# COMPUTE_CLUSTER_J7AHP0_CFG_WRAP_0_VBUSP4_CFG_AW6_CFG_MSMC1_ECC1 register map
Vendor: Texas Instruments
Peripheral module from a debugger description file (folder J7_AHP).
Registers are 32-bit, access not given, reset 0x0 unless marked. A register's access mark holds for its fields unless they carry their own. Offsets are as the file gives them; lines under a group give offsets from that group; [hi:lo] are bit positions; {n}, {i} and the like mark numbered series; 'fields as' and 'values as' point back to an identical list; <NAME> marks a mode.

## COMPUTE_CLUSTER_J7AHP0_CFG_WRAP_0_VBUSP4_CFG_AW6_CFG_MSMC1_ECC1
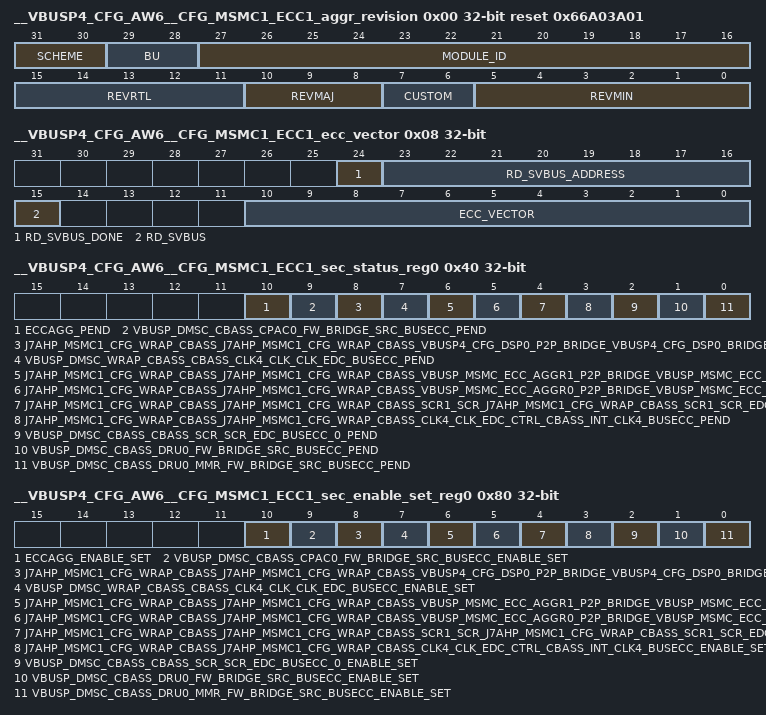
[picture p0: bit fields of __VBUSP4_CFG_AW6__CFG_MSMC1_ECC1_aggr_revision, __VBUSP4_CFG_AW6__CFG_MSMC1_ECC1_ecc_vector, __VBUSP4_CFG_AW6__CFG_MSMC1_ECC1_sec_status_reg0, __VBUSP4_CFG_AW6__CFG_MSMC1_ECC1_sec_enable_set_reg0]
0x00 __VBUSP4_CFG_AW6__CFG_MSMC1_ECC1_aggr_revision ro reset 0x66A03A01
  [31:30] SCHEME
  [29:28] BU
  [27:16] MODULE_ID
  [15:11] REVRTL — RTL version
  [10:8] REVMAJ — Major version
  [7:6] CUSTOM — Custom version
  [5:0] REVMIN — Minor version
0x08 __VBUSP4_CFG_AW6__CFG_MSMC1_ECC1_ecc_vector
  [24] RD_SVBUS_DONE — Status to indicate if read on serial VBUS is complete, write of any value will clear this bit. (access R/W1TC)
  [23:16] RD_SVBUS_ADDRESS rw — Read address
  [15] RD_SVBUS — Write 1 to trigger a read on the serial VBUS (access R/W1TS)
  [10:0] ECC_VECTOR rw — Value written to select the corresponding ECC RAM for control or status
0x0C __VBUSP4_CFG_AW6__CFG_MSMC1_ECC1_misc_status ro reset 0xB
  [10:0] NUM_RAMS — Indicates the number of RAMS serviced by the ECC aggregator
0x10 __VBUSP4_CFG_AW6__CFG_MSMC1_ECC1_reserved_svbus rw
  [31:0] DATA — Serial VBUS register data
0x3C __VBUSP4_CFG_AW6__CFG_MSMC1_ECC1_sec_eoi_reg
  [0] EOI_WR — EOI Register (access R/W1TS)
0x40 __VBUSP4_CFG_AW6__CFG_MSMC1_ECC1_sec_status_reg0
  [10] ECCAGG_PEND — Interrupt Pending Status for eccagg_pend (access R/W1TS)
  [9] VBUSP_DMSC_CBASS_CPAC0_FW_BRIDGE_SRC_BUSECC_PEND — Interrupt Pending Status for vbusp_dmsc_cbass_cpac0_fw_bridge_src_busecc_pend (access R/W1TS)
  [8] J7AHP_MSMC1_CFG_WRAP_CBASS_J7AHP_MSMC1_CFG_WRAP_CBASS_VBUSP4_CFG_DSP0_P2P_BRIDGE_VBUSP4_CFG_DSP0_BRIDGE_SRC_BUSECC_PEND — Interrupt Pending Status for j7ahp_msmc1_cfg_wrap_cbass_j7ahp_msmc1_cfg_wrap_cbass_vbusp4_cfg_dsp0_p2p_bridge_vbusp4_cfg_dsp0_bridge_src_busecc_pend (access R/W1TS)
  [7] VBUSP_DMSC_WRAP_CBASS_CBASS_CLK4_CLK_CLK_EDC_BUSECC_PEND — Interrupt Pending Status for vbusp_dmsc_wrap_cbass_cbass_clk4_clk_clk_edc_busecc_pend (access R/W1TS)
  [6] J7AHP_MSMC1_CFG_WRAP_CBASS_J7AHP_MSMC1_CFG_WRAP_CBASS_VBUSP_MSMC_ECC_AGGR1_P2P_BRIDGE_VBUSP_MSMC_ECC_AGGR1_BRIDGE_BUSECC_PEND — Interrupt Pending Status for j7ahp_msmc1_cfg_wrap_cbass_j7ahp_msmc1_cfg_wrap_cbass_vbusp_msmc_ecc_aggr1_p2p_bridge_vbusp_msmc_ecc_aggr1_bridge_busecc_pend (access R/W1TS)
  [5] J7AHP_MSMC1_CFG_WRAP_CBASS_J7AHP_MSMC1_CFG_WRAP_CBASS_VBUSP_MSMC_ECC_AGGR0_P2P_BRIDGE_VBUSP_MSMC_ECC_AGGR0_BRIDGE_SRC_BUSECC_PEND — Interrupt Pending Status for j7ahp_msmc1_cfg_wrap_cbass_j7ahp_msmc1_cfg_wrap_cbass_vbusp_msmc_ecc_aggr0_p2p_bridge_vbusp_msmc_ecc_aggr0_bridge_src_busecc_pend (access R/W1TS)
  [4] J7AHP_MSMC1_CFG_WRAP_CBASS_J7AHP_MSMC1_CFG_WRAP_CBASS_SCR1_SCR_J7AHP_MSMC1_CFG_WRAP_CBASS_SCR1_SCR_EDC_CTRL_BUSECC_PEND — Interrupt Pending Status for j7ahp_msmc1_cfg_wrap_cbass_j7ahp_msmc1_cfg_wrap_cbass_scr1_scr_j7ahp_msmc1_cfg_wrap_cbass_scr1_scr_edc_ctrl_busecc_pend (access R/W1TS)
  [3] J7AHP_MSMC1_CFG_WRAP_CBASS_J7AHP_MSMC1_CFG_WRAP_CBASS_CLK4_CLK_EDC_CTRL_CBASS_INT_CLK4_BUSECC_PEND — Interrupt Pending Status for j7ahp_msmc1_cfg_wrap_cbass_j7ahp_msmc1_cfg_wrap_cbass_clk4_clk_edc_ctrl_cbass_int_clk4_busecc_pend (access R/W1TS)
  [2] VBUSP_DMSC_CBASS_CBASS_SCR_SCR_EDC_BUSECC_0_PEND — Interrupt Pending Status for vbusp_dmsc_cbass_cbass_scr_scr_edc_busecc_0_pend (access R/W1TS)
  [1] VBUSP_DMSC_CBASS_DRU0_FW_BRIDGE_SRC_BUSECC_PEND — Interrupt Pending Status for vbusp_dmsc_cbass_dru0_fw_bridge_src_busecc_pend (access R/W1TS)
  [0] VBUSP_DMSC_CBASS_DRU0_MMR_FW_BRIDGE_SRC_BUSECC_PEND — Interrupt Pending Status for vbusp_dmsc_cbass_dru0_mmr_fw_bridge_src_busecc_pend (access R/W1TS)
0x80 __VBUSP4_CFG_AW6__CFG_MSMC1_ECC1_sec_enable_set_reg0
  [10] ECCAGG_ENABLE_SET — Interrupt Enable Set Register for eccagg_pend (access R/W1TS)
  [9] VBUSP_DMSC_CBASS_CPAC0_FW_BRIDGE_SRC_BUSECC_ENABLE_SET — Interrupt Enable Set Register for vbusp_dmsc_cbass_cpac0_fw_bridge_src_busecc_pend (access R/W1TS)
  [8] J7AHP_MSMC1_CFG_WRAP_CBASS_J7AHP_MSMC1_CFG_WRAP_CBASS_VBUSP4_CFG_DSP0_P2P_BRIDGE_VBUSP4_CFG_DSP0_BRIDGE_SRC_BUSECC_ENABLE_SET — Interrupt Enable Set Register for j7ahp_msmc1_cfg_wrap_cbass_j7ahp_msmc1_cfg_wrap_cbass_vbusp4_cfg_dsp0_p2p_bridge_vbusp4_cfg_dsp0_bridge_src_busecc_pend (access R/W1TS)
  [7] VBUSP_DMSC_WRAP_CBASS_CBASS_CLK4_CLK_CLK_EDC_BUSECC_ENABLE_SET — Interrupt Enable Set Register for vbusp_dmsc_wrap_cbass_cbass_clk4_clk_clk_edc_busecc_pend (access R/W1TS)
  [6] J7AHP_MSMC1_CFG_WRAP_CBASS_J7AHP_MSMC1_CFG_WRAP_CBASS_VBUSP_MSMC_ECC_AGGR1_P2P_BRIDGE_VBUSP_MSMC_ECC_AGGR1_BRIDGE_BUSECC_ENABLE_SET — Interrupt Enable Set Register for j7ahp_msmc1_cfg_wrap_cbass_j7ahp_msmc1_cfg_wrap_cbass_vbusp_msmc_ecc_aggr1_p2p_bridge_vbusp_msmc_ecc_aggr1_bridge_busecc_pend (access R/W1TS)
  [5] J7AHP_MSMC1_CFG_WRAP_CBASS_J7AHP_MSMC1_CFG_WRAP_CBASS_VBUSP_MSMC_ECC_AGGR0_P2P_BRIDGE_VBUSP_MSMC_ECC_AGGR0_BRIDGE_SRC_BUSECC_ENABLE_SET — Interrupt Enable Set Register for j7ahp_msmc1_cfg_wrap_cbass_j7ahp_msmc1_cfg_wrap_cbass_vbusp_msmc_ecc_aggr0_p2p_bridge_vbusp_msmc_ecc_aggr0_bridge_src_busecc_pend (access R/W1TS)
  [4] J7AHP_MSMC1_CFG_WRAP_CBASS_J7AHP_MSMC1_CFG_WRAP_CBASS_SCR1_SCR_J7AHP_MSMC1_CFG_WRAP_CBASS_SCR1_SCR_EDC_CTRL_BUSECC_ENABLE_SET — Interrupt Enable Set Register for j7ahp_msmc1_cfg_wrap_cbass_j7ahp_msmc1_cfg_wrap_cbass_scr1_scr_j7ahp_msmc1_cfg_wrap_cbass_scr1_scr_edc_ctrl_busecc_pend (access R/W1TS)
  [3] J7AHP_MSMC1_CFG_WRAP_CBASS_J7AHP_MSMC1_CFG_WRAP_CBASS_CLK4_CLK_EDC_CTRL_CBASS_INT_CLK4_BUSECC_ENABLE_SET — Interrupt Enable Set Register for j7ahp_msmc1_cfg_wrap_cbass_j7ahp_msmc1_cfg_wrap_cbass_clk4_clk_edc_ctrl_cbass_int_clk4_busecc_pend (access R/W1TS)
  [2] VBUSP_DMSC_CBASS_CBASS_SCR_SCR_EDC_BUSECC_0_ENABLE_SET — Interrupt Enable Set Register for vbusp_dmsc_cbass_cbass_scr_scr_edc_busecc_0_pend (access R/W1TS)
  [1] VBUSP_DMSC_CBASS_DRU0_FW_BRIDGE_SRC_BUSECC_ENABLE_SET — Interrupt Enable Set Register for vbusp_dmsc_cbass_dru0_fw_bridge_src_busecc_pend (access R/W1TS)
  [0] VBUSP_DMSC_CBASS_DRU0_MMR_FW_BRIDGE_SRC_BUSECC_ENABLE_SET — Interrupt Enable Set Register for vbusp_dmsc_cbass_dru0_mmr_fw_bridge_src_busecc_pend (access R/W1TS)
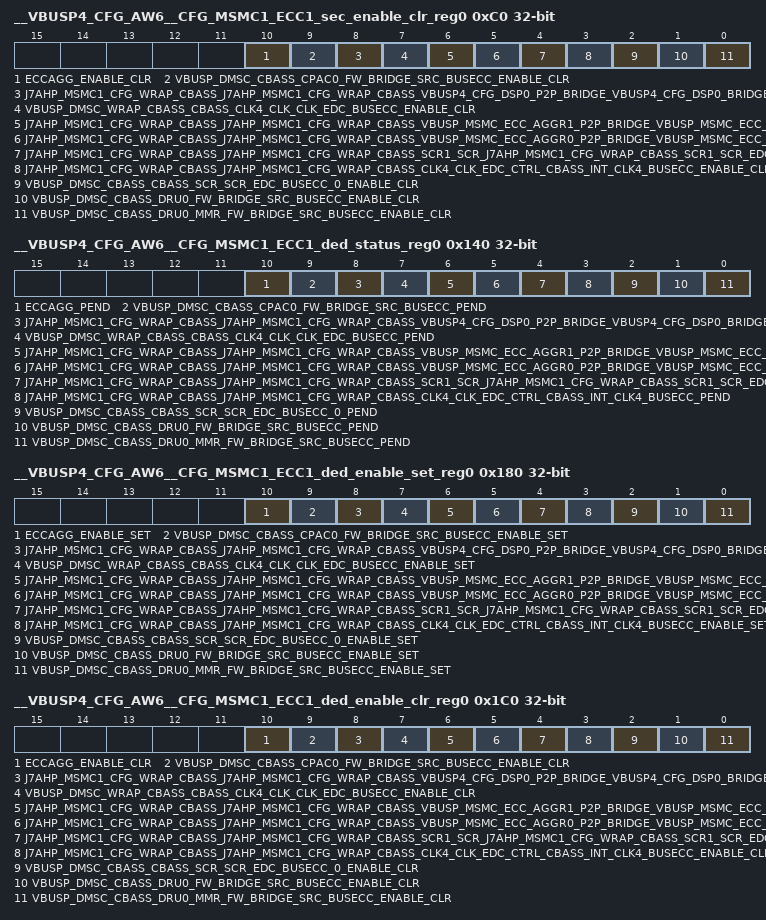
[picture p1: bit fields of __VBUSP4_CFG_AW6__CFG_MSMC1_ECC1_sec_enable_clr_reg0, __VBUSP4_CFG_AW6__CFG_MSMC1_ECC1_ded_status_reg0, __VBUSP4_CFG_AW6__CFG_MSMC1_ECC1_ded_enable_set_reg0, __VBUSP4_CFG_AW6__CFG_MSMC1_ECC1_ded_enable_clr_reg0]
0xC0 __VBUSP4_CFG_AW6__CFG_MSMC1_ECC1_sec_enable_clr_reg0
  [10] ECCAGG_ENABLE_CLR — Interrupt Enable Clear Register for eccagg_pend (access R/W1TC)
  [9] VBUSP_DMSC_CBASS_CPAC0_FW_BRIDGE_SRC_BUSECC_ENABLE_CLR — Interrupt Enable Clear Register for vbusp_dmsc_cbass_cpac0_fw_bridge_src_busecc_pend (access R/W1TC)
  [8] J7AHP_MSMC1_CFG_WRAP_CBASS_J7AHP_MSMC1_CFG_WRAP_CBASS_VBUSP4_CFG_DSP0_P2P_BRIDGE_VBUSP4_CFG_DSP0_BRIDGE_SRC_BUSECC_ENABLE_CLR — Interrupt Enable Clear Register for j7ahp_msmc1_cfg_wrap_cbass_j7ahp_msmc1_cfg_wrap_cbass_vbusp4_cfg_dsp0_p2p_bridge_vbusp4_cfg_dsp0_bridge_src_busecc_pend (access R/W1TC)
  [7] VBUSP_DMSC_WRAP_CBASS_CBASS_CLK4_CLK_CLK_EDC_BUSECC_ENABLE_CLR — Interrupt Enable Clear Register for vbusp_dmsc_wrap_cbass_cbass_clk4_clk_clk_edc_busecc_pend (access R/W1TC)
  [6] J7AHP_MSMC1_CFG_WRAP_CBASS_J7AHP_MSMC1_CFG_WRAP_CBASS_VBUSP_MSMC_ECC_AGGR1_P2P_BRIDGE_VBUSP_MSMC_ECC_AGGR1_BRIDGE_BUSECC_ENABLE_CLR — Interrupt Enable Clear Register for j7ahp_msmc1_cfg_wrap_cbass_j7ahp_msmc1_cfg_wrap_cbass_vbusp_msmc_ecc_aggr1_p2p_bridge_vbusp_msmc_ecc_aggr1_bridge_busecc_pend (access R/W1TC)
  [5] J7AHP_MSMC1_CFG_WRAP_CBASS_J7AHP_MSMC1_CFG_WRAP_CBASS_VBUSP_MSMC_ECC_AGGR0_P2P_BRIDGE_VBUSP_MSMC_ECC_AGGR0_BRIDGE_SRC_BUSECC_ENABLE_CLR — Interrupt Enable Clear Register for j7ahp_msmc1_cfg_wrap_cbass_j7ahp_msmc1_cfg_wrap_cbass_vbusp_msmc_ecc_aggr0_p2p_bridge_vbusp_msmc_ecc_aggr0_bridge_src_busecc_pend (access R/W1TC)
  [4] J7AHP_MSMC1_CFG_WRAP_CBASS_J7AHP_MSMC1_CFG_WRAP_CBASS_SCR1_SCR_J7AHP_MSMC1_CFG_WRAP_CBASS_SCR1_SCR_EDC_CTRL_BUSECC_ENABLE_CLR — Interrupt Enable Clear Register for j7ahp_msmc1_cfg_wrap_cbass_j7ahp_msmc1_cfg_wrap_cbass_scr1_scr_j7ahp_msmc1_cfg_wrap_cbass_scr1_scr_edc_ctrl_busecc_pend (access R/W1TC)
  [3] J7AHP_MSMC1_CFG_WRAP_CBASS_J7AHP_MSMC1_CFG_WRAP_CBASS_CLK4_CLK_EDC_CTRL_CBASS_INT_CLK4_BUSECC_ENABLE_CLR — Interrupt Enable Clear Register for j7ahp_msmc1_cfg_wrap_cbass_j7ahp_msmc1_cfg_wrap_cbass_clk4_clk_edc_ctrl_cbass_int_clk4_busecc_pend (access R/W1TC)
  [2] VBUSP_DMSC_CBASS_CBASS_SCR_SCR_EDC_BUSECC_0_ENABLE_CLR — Interrupt Enable Clear Register for vbusp_dmsc_cbass_cbass_scr_scr_edc_busecc_0_pend (access R/W1TC)
  [1] VBUSP_DMSC_CBASS_DRU0_FW_BRIDGE_SRC_BUSECC_ENABLE_CLR — Interrupt Enable Clear Register for vbusp_dmsc_cbass_dru0_fw_bridge_src_busecc_pend (access R/W1TC)
  [0] VBUSP_DMSC_CBASS_DRU0_MMR_FW_BRIDGE_SRC_BUSECC_ENABLE_CLR — Interrupt Enable Clear Register for vbusp_dmsc_cbass_dru0_mmr_fw_bridge_src_busecc_pend (access R/W1TC)
0x13C __VBUSP4_CFG_AW6__CFG_MSMC1_ECC1_ded_eoi_reg
  [0] EOI_WR — EOI Register (access R/W1TS)
0x140 __VBUSP4_CFG_AW6__CFG_MSMC1_ECC1_ded_status_reg0
  fields as __VBUSP4_CFG_AW6__CFG_MSMC1_ECC1_sec_status_reg0
0x180 __VBUSP4_CFG_AW6__CFG_MSMC1_ECC1_ded_enable_set_reg0
  fields as __VBUSP4_CFG_AW6__CFG_MSMC1_ECC1_sec_enable_set_reg0
0x1C0 __VBUSP4_CFG_AW6__CFG_MSMC1_ECC1_ded_enable_clr_reg0
  fields as __VBUSP4_CFG_AW6__CFG_MSMC1_ECC1_sec_enable_clr_reg0
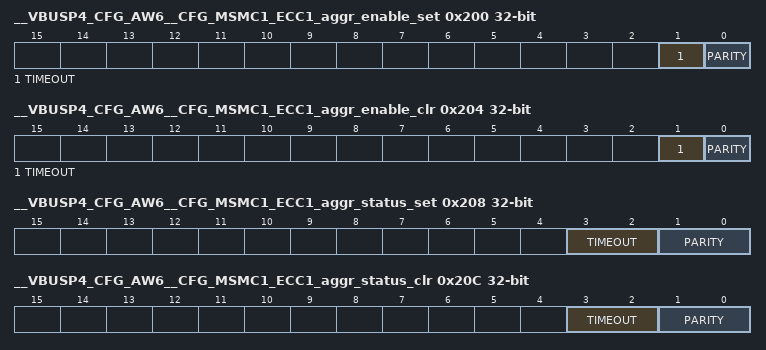
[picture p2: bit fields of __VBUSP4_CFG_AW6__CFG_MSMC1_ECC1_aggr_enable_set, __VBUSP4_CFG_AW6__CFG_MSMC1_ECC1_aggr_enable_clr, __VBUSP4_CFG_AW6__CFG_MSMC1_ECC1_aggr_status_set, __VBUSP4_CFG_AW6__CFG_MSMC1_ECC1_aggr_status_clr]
0x200 __VBUSP4_CFG_AW6__CFG_MSMC1_ECC1_aggr_enable_set
  [1] TIMEOUT — interrupt enable set for svbus timeout errors (access R/W1TS)
  [0] PARITY — interrupt enable set for parity errors (access R/W1TS)
0x204 __VBUSP4_CFG_AW6__CFG_MSMC1_ECC1_aggr_enable_clr
  [1] TIMEOUT — interrupt enable clear for svbus timeout errors (access R/W1TC)
  [0] PARITY — interrupt enable clear for parity errors (access R/W1TC)
0x208 __VBUSP4_CFG_AW6__CFG_MSMC1_ECC1_aggr_status_set
  [3:2] TIMEOUT — interrupt status set for svbus timeout errors (access R/WI)
  [1:0] PARITY — interrupt status set for parity errors (access R/WI)
0x20C __VBUSP4_CFG_AW6__CFG_MSMC1_ECC1_aggr_status_clr
  [3:2] TIMEOUT — interrupt status clear for svbus timeout errors (access R/WD)
  [1:0] PARITY — interrupt status clear for parity errors (access R/WD)
